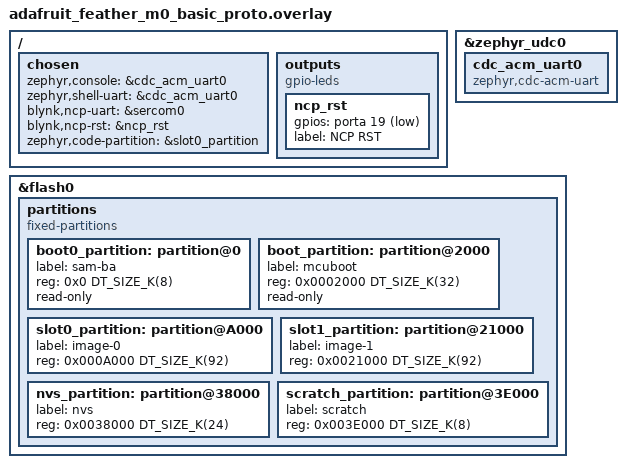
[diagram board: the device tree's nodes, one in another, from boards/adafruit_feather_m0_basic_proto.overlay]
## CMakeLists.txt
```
#
# Copyright (c) 2024 Blynk Technologies Inc.
#
# SPDX-License-Identifier: Apache-2.0
#

cmake_minimum_required(VERSION 3.20.0)
find_package(Zephyr REQUIRED HINTS $ENV{ZEPHYR_BASE})
project(blynk_over_zephyr)

target_sources(app PRIVATE src/main.c)

zephyr_get_include_directories_for_lang_as_string(       C includes)
zephyr_get_system_include_directories_for_lang_as_string(C system_includes)
zephyr_get_compile_definitions_for_lang_as_string(       C definitions)
zephyr_get_compile_options_for_lang_as_string(           C options)

set(blynk_ncp_cflags
  "${includes} ${definitions} ${options} ${system_includes}"
  )

include(ExternalProject)

# Add an external project to be able download and build the third
# party library. In this case downloading is not necessary as it has
# been committed to the repository.
set(blynk_ncp_src_dir   ${CMAKE_CURRENT_SOURCE_DIR}/../../blynk_ncp)
set(blynk_ncp_build_dir ${CMAKE_CURRENT_BINARY_DIR}/blynk_ncp)

set(BLYNK_NCP_DIR     ${blynk_ncp_build_dir}/lib)
set(BLYNK_INCLUDE_DIR ${blynk_ncp_src_dir}/src/BlynkNcpDriver/src)

if(CMAKE_GENERATOR STREQUAL "Unix Makefiles")
# https://www.gnu.org/software/make/manual/html_node/MAKE-Variable.html
set(submake "$(MAKE)")
else() # Obviously no MAKEFLAGS. Let's hope a "make" can be found somewhere.
set(submake "make")
endif()

ExternalProject_Add(
  blynk_example                 # Name for custom target
  PREFIX     ${blynk_ncp_build_dir} # Root dir for entire project
  SOURCE_DIR ${blynk_ncp_src_dir}
  BINARY_DIR ${blynk_ncp_src_dir} # This particular build system is invoked from the root
  CONFIGURE_COMMAND ""    # Skip configuring the project, e.g. with autoconf
  BUILD_COMMAND
  ${submake}
  PREFIX=${blynk_ncp_build_dir}
  CC=${CMAKE_C_COMPILER}
  AR=${CMAKE_AR}
  CFLAGS=${blynk_ncp_cflags}
  INSTALL_COMMAND ""      # This particular build system has no install command
  BUILD_BYPRODUCTS ${BLYNK_NCP_DIR}/libblynkncp.a
  DEPENDS zephyr_interface
  )

# Create a wrapper CMake library that our app can link with
add_library(blynk_ncp_lib STATIC IMPORTED GLOBAL)
add_dependencies(
  blynk_ncp_lib
  blynk_example
  )

list(APPEND LIB_INCLUDE_DIRS ${BLYNK_INCLUDE_DIR})
list(APPEND LIB_INCLUDE_DIRS ${blynk_ncp_src_dir}/include)

set_target_properties(blynk_ncp_lib PROPERTIES IMPORTED_LOCATION             ${BLYNK_NCP_DIR}/libblynkncp.a)
set_target_properties(blynk_ncp_lib PROPERTIES INTERFACE_INCLUDE_DIRECTORIES "${LIB_INCLUDE_DIRS}")

target_link_libraries(app PUBLIC blynk_ncp_lib)
target_link_libraries(blynk_ncp_lib INTERFACE kernel)
```

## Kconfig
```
# Config options for Blynk.NCP driver

# Copyright (c) 2024 Blynk Technologies Inc.
# SPDX-License-Identifier: Apache-2.0

rsource "../../blynk_ncp/Kconfig.blynk_ncp"
source "Kconfig.zephyr"
```

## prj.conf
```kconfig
CONFIG_SERIAL=y
CONFIG_GPIO=y
CONFIG_UART_INTERRUPT_DRIVEN=y
CONFIG_UART_USE_RUNTIME_CONFIGURE=y
CONFIG_LOG=y
CONFIG_RING_BUFFER=y

CONFIG_STREAM_FLASH=y
CONFIG_BOOTLOADER_MCUBOOT=y
CONFIG_MCUBOOT_SIGNATURE_KEY_FILE="bootloader/mcuboot/root-rsa-2048.pem"
CONFIG_MCUBOOT_GENERATE_CONFIRMED_IMAGE=y
CONFIG_MCUBOOT_IMGTOOL_SIGN_VERSION="0.0.1"
CONFIG_MCUBOOT_BOOTLOADER_MODE_SWAP_SCRATCH=y
CONFIG_MCUBOOT_BOOTUTIL_LIB=y

CONFIG_MCUBOOT_IMG_MANAGER=y
CONFIG_FLASH=y
CONFIG_FLASH_MAP=y
CONFIG_FLASH_PAGE_LAYOUT=y
CONFIG_REBOOT=y
CONFIG_IMG_MANAGER=y
CONFIG_MPU_ALLOW_FLASH_WRITE=y
CONFIG_HEAP_MEM_POOL_SIZE=2048
```

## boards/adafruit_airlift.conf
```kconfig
# Copyright (c) 2024 Blynk Technologies Inc.
# SPDX-License-Identifier: Apache-2.0

# Status RGB LED
CONFIG_BLYNK_NCP_ONBOARD_RGB_LED=y
CONFIG_BLYNK_NCP_ONBOARD_RGB_R_GPIO_NUM=26
CONFIG_BLYNK_NCP_ONBOARD_RGB_G_GPIO_NUM=25
CONFIG_BLYNK_NCP_ONBOARD_RGB_B_GPIO_NUM=27
```

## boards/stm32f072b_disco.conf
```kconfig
CONFIG_HEAP_MEM_POOL_SIZE=1024
CONFIG_BLYNK_UART_TX_BUF_SIZE=512
CONFIG_BLYNK_UART_RX_BUF_SIZE=1536
CONFIG_BLYNK_THERAD_STACK_SIZE=512
```

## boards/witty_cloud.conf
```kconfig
# Copyright (c) 2024 Blynk Technologies Inc.
# SPDX-License-Identifier: Apache-2.0

# Status RGB LED
CONFIG_BLYNK_NCP_ONBOARD_RGB_LED=y
CONFIG_BLYNK_NCP_ONBOARD_RGB_R_GPIO_NUM=15
CONFIG_BLYNK_NCP_ONBOARD_RGB_G_GPIO_NUM=12
CONFIG_BLYNK_NCP_ONBOARD_RGB_B_GPIO_NUM=13
CONFIG_BLYNK_NCP_ONBOARD_LED_BRIGHT=128

# User button
CONFIG_BLYNK_NCP_ONBOARD_BTN=y
CONFIG_BLYNK_NCP_ONBOARD_BTN_GPIO_NUM=4
CONFIG_BLYNK_NCP_ONBOARD_BTN_INVERSION=1
```

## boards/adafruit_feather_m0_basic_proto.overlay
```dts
/*
 * Copyright (c) 2024 Blynk Technologies Inc.
 *
 * SPDX-License-Identifier: Apache-2.0
 */


/ {
    chosen {
        zephyr,console = &cdc_acm_uart0;
        zephyr,shell-uart = &cdc_acm_uart0;
        blynk,ncp-uart = &sercom0;
        blynk,ncp-rst = &ncp_rst;
        zephyr,code-partition = &slot0_partition;
    };

    outputs {
        compatible = "gpio-leds";
        ncp_rst: ncp_rst {
            gpios = <&porta 19 GPIO_ACTIVE_LOW>; /* D12 */
            label = "NCP RST";
        };
    };
};

&zephyr_udc0 {
    cdc_acm_uart0: cdc_acm_uart0 {
        compatible = "zephyr,cdc-acm-uart";
    };
};

/* Remove default partitions */
/delete-node/ &boot_partition;
/delete-node/ &code_partition;
/delete-node/ &storage_partition;

&flash0 {
    partitions {
        compatible = "fixed-partitions";
        #address-cells = <1>;
        #size-cells = <1>;

        boot0_partition: partition@0 {
            label = "sam-ba";
            reg = <0x0 DT_SIZE_K(8)>;
            read-only;
        };
        boot_partition: partition@2000 {
            label = "mcuboot";
            reg = <0x0002000 DT_SIZE_K(32)>;
            read-only;
        };
        slot0_partition: partition@A000 {
            label = "image-0";
            reg = <0x000A000 DT_SIZE_K(92)>;
        };
        slot1_partition: partition@21000 {
            label = "image-1";
            reg = <0x0021000 DT_SIZE_K(92)>;
        };
        nvs_partition: partition@38000 {
            label = "nvs";
            reg = <0x0038000 DT_SIZE_K(24)>;
        };
        scratch_partition: partition@3E000 {
            label = "scratch";
            reg = <0x003E000 DT_SIZE_K(8)>;
        };
    };
};
```

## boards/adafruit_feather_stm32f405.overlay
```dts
/*
 * Copyright (c) 2024 Blynk Technologies Inc.
 *
 * SPDX-License-Identifier: Apache-2.0
 */


/ {
    chosen {
        zephyr,console = &cdc_acm_uart0;
        zephyr,shell-uart = &cdc_acm_uart0;
        blynk,ncp-uart = &feather_serial;
        blynk,ncp-rst = &ncp_rst;
        zephyr,code-partition = &slot0_partition;
    };

    outputs {
        compatible = "gpio-leds";
        ncp_rst: ncp_rst {
            gpios = <&feather_header 19 GPIO_ACTIVE_LOW>; /* D12 */
            label = "NCP RST";
        };
    };
};

&zephyr_udc0 {
    cdc_acm_uart0: cdc_acm_uart0 {
        compatible = "zephyr,cdc-acm-uart";
    };
};

&flash0 {
    partitions {
        compatible = "fixed-partitions";
        #address-cells = <1>;
        #size-cells = <1>;

        boot_partition: partition@0 {
            label = "mcuboot";
            reg = <0x0000000 0x10000>;
            read-only;
        };
        nvs_partition: partition@10000 {
            label = "nvs";
            reg = <0x0010000 0x10000>;
        };
        slot0_partition: partition@20000 {
            label = "image-0";
            reg = <0x0020000 0x60000>;
        };
        slot1_partition: partition@80000 {
            label = "image-1";
            reg = <0x0080000 0x60000>;
        };
        scratch_partition: partition@E0000 {
            label = "scratch";
            reg = <0x00E0000 0x20000>;
        };
    };
};
```

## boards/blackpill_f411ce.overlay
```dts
/*
 * Copyright (c) 2024 Blynk Technologies Inc.
 *
 * SPDX-License-Identifier: Apache-2.0
 */


/ {
    chosen {
        zephyr,console = &cdc_acm_uart0;
        zephyr,shell-uart = &cdc_acm_uart0;
        blynk,ncp-uart = &usart2;
        blynk,ncp-rst = &ncp_rst;
        blynk,ncp-status-led = &user_led;
        zephyr,code-partition = &slot0_partition;
    };

    outputs {
        compatible = "gpio-leds";
        ncp_rst: ncp_rst {
            gpios = <&gpioa 5 GPIO_ACTIVE_LOW>; // A5 header pin
            label = "NCP RST";
        };
    };
};

&zephyr_udc0 {
    cdc_acm_uart0: cdc_acm_uart0 {
        compatible = "zephyr,cdc-acm-uart";
    };
};

&usart2 {
    pinctrl-0 = <&usart2_tx_pa2 &usart2_rx_pa3>;
    pinctrl-names = "default";
    status = "okay";
    current-speed = <38400>;
};

/*
 * MCUboot-compatible partitions are already defined for this board
 */
```

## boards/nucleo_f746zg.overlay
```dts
/*
 * Copyright (c) 2024 Blynk Technologies Inc.
 *
 * SPDX-License-Identifier: Apache-2.0
 */


/ {
    chosen {
        zephyr,console = &uart5;
        zephyr,shell-uart = &uart5;
        blynk,ncp-uart = &usart2;
        zephyr,code-partition = &slot0_partition;
    };
};

&uart5 {
    pinctrl-0 = <&uart5_tx_pc12 &uart5_rx_pd2>;
    pinctrl-names = "default";
    current-speed = <115200>;
    status = "okay";
};

&usart2 {
    pinctrl-0 = <&usart2_tx_pd5 &usart2_rx_pd6>;
    pinctrl-names = "default";
    current-speed = <38400>;
    status = "okay";
};

&flash0 {
    partitions {
        compatible = "fixed-partitions";
        #address-cells = <1>;
        #size-cells = <1>;

        boot_partition: partition@0 {
            label = "mcuboot";
            reg = <0x0000000 0x20000>;
            read-only;
        };
        nvs_partition: partition@20000 {
            label = "nvs";
            reg = <0x0020000 0x00020000>;
        };
        slot0_partition: partition@40000 {
            label = "image-0";
            reg = <0x0040000 0x40000>;
        };
        slot1_partition: partition@80000 {
            label = "image-1";
            reg = <0x0080000 0x40000>;
        };
        scratch_partition: partition@C0000 {
            label = "scratch";
            reg = <0x00C0000 0x40000>;
        };
    };
};
```

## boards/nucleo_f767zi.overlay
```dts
/*
 * Copyright (c) 2024 Blynk Technologies Inc.
 *
 * SPDX-License-Identifier: Apache-2.0
 */


/ {
    chosen {
        zephyr,console = &usart3;
        zephyr,shell-uart = &usart3;
        blynk,ncp-uart = &usart2;
    };
};

&usart3 {
    pinctrl-0 = <&usart3_tx_pd8 &usart3_rx_pd9>;
    pinctrl-names = "default";
    current-speed = <115200>;
    status = "okay";
};

&usart2 {
    pinctrl-0 = <&usart2_tx_pd5 &usart2_rx_pd6>;
    pinctrl-names = "default";
    current-speed = <38400>;
    status = "okay";
};

/*
 * MCUboot-compatible partitions are already defined for this board
 */
```

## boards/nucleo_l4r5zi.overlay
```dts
/*
 * Copyright (c) 2024 Blynk Technologies Inc.
 *
 * SPDX-License-Identifier: Apache-2.0
 */


/ {
    chosen {
        zephyr,console = &usart2;
        zephyr,shell-uart = &usart2;
        blynk,ncp-uart = &arduino_serial;
        blynk,ncp-status-led = &blue_led_0;
        blynk,ncp-rst = &ncp_rst;
        zephyr,code-partition = &slot0_partition;
    };

    outputs {
        compatible = "gpio-leds";
        ncp_rst: ncp_rst {
            gpios = <&arduino_header 11 GPIO_ACTIVE_LOW>; /* D5 */
            label = "NCP RST";
        };
    };
};

&usart2 {
    current-speed = <115200>;
    status = "okay";
};

/* Remove default partitions */
/delete-node/ &storage_partition;

&flash0 {
    partitions {
        compatible = "fixed-partitions";
        #address-cells = <1>;
        #size-cells = <1>;

        boot_partition: partition@0 {
            label = "mcuboot";
            reg = <0x0000000 0x20000>;
            read-only;
        };
        nvs_partition: partition@20000 {
            label = "nvs";
            reg = <0x0020000 0x00020000>;
        };
        slot0_partition: partition@40000 {
            label = "image-0";
            reg = <0x0040000 0x40000>;
        };
        slot1_partition: partition@80000 {
            label = "image-1";
            reg = <0x0080000 0x40000>;
        };
        scratch_partition: partition@C0000 {
            label = "scratch";
            reg = <0x00C0000 0x40000>;
        };
    };
};
```

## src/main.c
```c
/*
 * Copyright (c) 2024 Blynk Technologies Inc.
 *
 * SPDX-License-Identifier: Apache-2.0
 */

#include <stdio.h>
#include <stdlib.h>
#include <string.h>

#include <zephyr/kernel.h>
#include <zephyr/logging/log.h>

#include <blynk_ncp/blynk_ncp.h>

LOG_MODULE_REGISTER(blynk_example, CONFIG_LOG_DEFAULT_LEVEL);

static void periodic_timer_work_handler(struct k_work *work)
{
    const uint32_t value = k_uptime_get_32();
    LOG_DBG("Sending %u to Virtual Pin 2", value);

    char buff[16];
    snprintf(buff, sizeof(buff), "%u", value);
    rpc_buffer_t val = {(uint8_t *)buff, strlen(buff)};
    rpc_blynk_virtualWrite(2 /*VPin*/, val);
}

K_WORK_DEFINE(periodic_timer_work, periodic_timer_work_handler);

static void periodic_timer_handler(struct k_timer *)
{
    k_work_submit(&periodic_timer_work);
}

K_TIMER_DEFINE(periodic_timer, periodic_timer_handler, NULL);

void rpc_client_blynkVPinChange_impl(uint16_t vpin, rpc_buffer_t param)
{
    switch (vpin) {
    case 0:
        /* VPin0 to VPin1 loopback */
        rpc_blynk_virtualWrite(1 /*VPin*/, param);
        break;
    case 1:
        /* VPin0 to VPin1 loopback */
        rpc_blynk_virtualWrite(0 /*VPin*/, param);
        break;
    default:
        LOG_WRN("unknown VPIN [%hu]", vpin);
        break;
    }
}

int main(void)
{
#if defined(CONFIG_USB_CDC_ACM)
    // Sleep to wait for a CDC connection
    k_msleep(3000);
#endif

    LOG_INF("Blynk.NCP host example on %s", CONFIG_BOARD);
    LOG_INF("Firmware version: %s", CONFIG_BLYNK_FIRMWARE_VERSION);

    // Mark OTA image as OK
    if (0 != boot_set_confirmed_multi(0)) {
        LOG_ERR("Can't confirm boot image");
    }

    // Initialize Blynk.NCP
    if (0 != blynk_ncp_init()) {
        LOG_ERR("Can't initialize Blynk.NCP");
        return 1;
    }

    while (BLYNK_STATE_NOT_INITIALIZED == blynk_ncp_get_state()) {
        k_msleep(20);
    }

    // Set the configuration mode timeout to 30 minutes (for demo purposes)
    rpc_blynk_setConfigTimeout(30 * 60);

    // Start a periodic timer
    k_timer_start(&periodic_timer, K_SECONDS(1), K_SECONDS(1));

    k_sleep(K_FOREVER);

    return 0;
}
```
